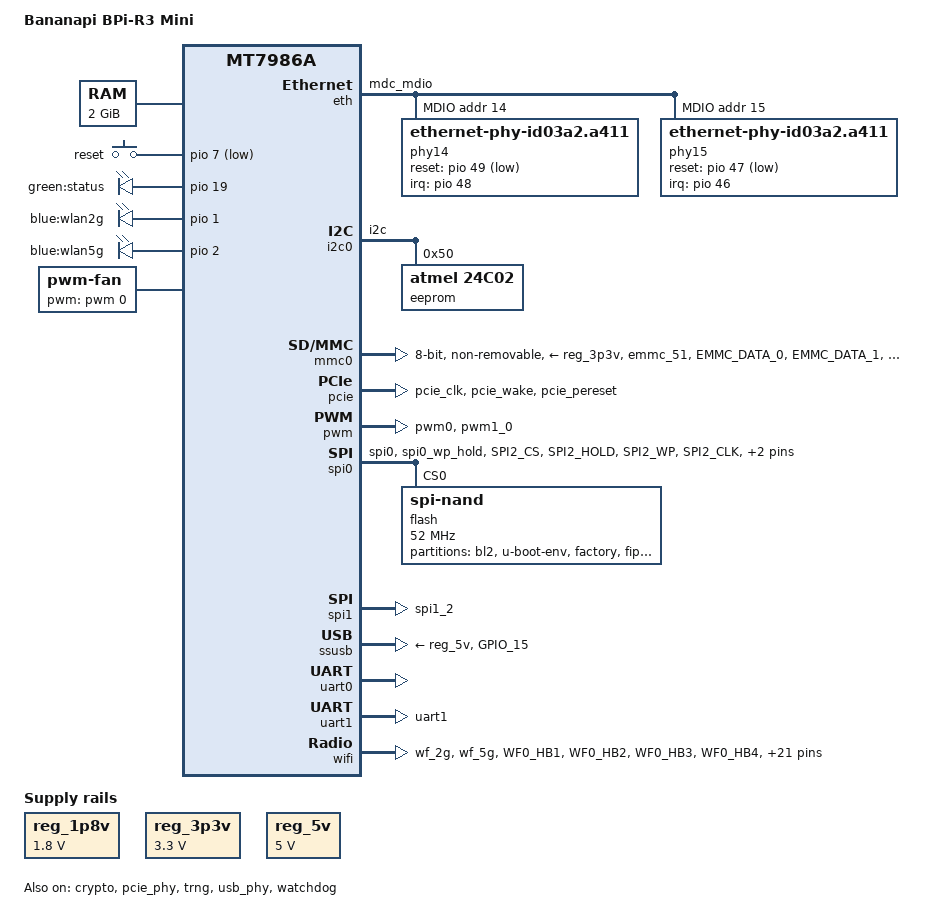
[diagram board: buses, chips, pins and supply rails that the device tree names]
// SPDX-License-Identifier: GPL-2.0-or-later OR MIT
/*
 * Copyright (C) 2023 Tianling Shen <cnsztl@immortalwrt.org>
 */

/dts-v1/;
#include <dt-bindings/gpio/gpio.h>
#include <dt-bindings/input/input.h>
#include <dt-bindings/leds/common.h>

#include "mt7986a.dtsi"

/ {
	model = "Bananapi BPi-R3 Mini";
	chassis-type = "embedded";
	compatible = "bananapi,bpi-r3-mini", "mediatek,mt7986a";

	aliases {
		ethernet0 = &gmac0;
		ethernet1 = &gmac1;
		serial0 = &uart0;

		led-boot = &status_led;
		led-failsafe = &status_led;
		led-running = &status_led;
		led-upgrade = &status_led;
	};

	chosen {
		stdout-path = "serial0:115200n8";
	};

	memory {
		reg = <0 0x40000000 0 0x80000000>;
	};

	gpio-keys {
		compatible = "gpio-keys";

		button-reset {
			label = "reset";
			linux,code = <KEY_RESTART>;
			gpios = <&pio 7 GPIO_ACTIVE_LOW>;
		};
	};

	gpio-leds {
		compatible = "gpio-leds";

		status_led: led-0 {
			label = "green:status";
			gpios = <&pio 19 GPIO_ACTIVE_HIGH>;
		};

		led-1 {
			label = "blue:wlan2g";
			gpios = <&pio 1 GPIO_ACTIVE_HIGH>;
		};

		led-2 {
			label = "blue:wlan5g";
			gpios = <&pio 2 GPIO_ACTIVE_HIGH>;
		};
	};

	fan: pwm-fan {
		compatible = "pwm-fan";
		#cooling-cells = <2>;
		cooling-levels = <0 128 255>;
		pwms = <&pwm 0 10000 0>;
		status = "okay";
	};

	reg_1p8v: regulator-1p8v {
		compatible = "regulator-fixed";
		regulator-name = "fixed-1.8V";
		regulator-min-microvolt = <1800000>;
		regulator-max-microvolt = <1800000>;
		regulator-boot-on;
		regulator-always-on;
	};

	reg_3p3v: regulator-3p3v {
		compatible = "regulator-fixed";
		regulator-name = "fixed-3.3V";
		regulator-min-microvolt = <3300000>;
		regulator-max-microvolt = <3300000>;
		regulator-boot-on;
		regulator-always-on;
	};

	reg_5v: regulator-5v {
		compatible = "regulator-fixed";
		regulator-name = "fixed-5V";
		regulator-min-microvolt = <5000000>;
		regulator-max-microvolt = <5000000>;
		regulator-boot-on;
		regulator-always-on;
	};
};

&cpu_thermal {
	cooling-maps {
		cpu-active-low {
			cooling-device = <&fan 0 0>;
			trip = <&cpu_trip_active_low>;
		};

		cpu-active-med {
			cooling-device = <&fan 1 1>;
			trip = <&cpu_trip_active_med>;
		};

		cpu-active-high {
			cooling-device = <&fan 2 2>;
			trip = <&cpu_trip_active_high>;
		};
	};
};

&crypto {
	status = "okay";
};

&eth {
	status = "okay";
	pinctrl-names = "default";
	pinctrl-0 = <&eth_pins>;

	gmac0: mac@0 {
		compatible = "mediatek,eth-mac";
		reg = <0>;
		phy-mode = "2500base-x";

		fixed-link {
			speed = <2500>;
			full-duplex;
			pause;
		};
	};

	gmac1: mac@1 {
		compatible = "mediatek,eth-mac";
		reg = <1>;
		phy-mode = "2500base-x";

		fixed-link {
			speed = <2500>;
			full-duplex;
			pause;
		};
	};

	mdio: mdio-bus {
		#address-cells = <1>;
		#size-cells = <0>;

		phy14: phy@14 {
			compatible = "ethernet-phy-id03a2.a411";
			reg = <14>;
			pinctrl-names = "default";
			pinctrl-0 = <&en8811_pwr_a>;

			airoha,rx-pol-reverse;

			interrupt-parent = <&pio>;
			interrupts = <48 IRQ_TYPE_LEVEL_HIGH>;
			reset-gpios = <&pio 49 1>;
			reset-assert-us = <10000>;
			reset-deassert-us = <20000>;

			phy-mode = "2500base-x";
			full-duplex;
			pause;
		};

		phy15: phy@15 {
			compatible = "ethernet-phy-id03a2.a411";
			reg = <15>;
			pinctrl-names = "default";
			pinctrl-0 = <&en8811_pwr_b>;

			airoha,rx-pol-reverse;

			interrupt-parent = <&pio>;
			interrupts = <46 IRQ_TYPE_LEVEL_HIGH>;
			reset-gpios = <&pio 47 1>;
			reset-assert-us = <10000>;
			reset-deassert-us = <20000>;

			phy-mode = "2500base-x";
			full-duplex;
			pause;
		};
	};
};

&i2c0 {
	pinctrl-names = "default";
	pinctrl-0 = <&i2c_pins>;
	status = "okay";

	eeprom@50 {
		compatible = "atmel,24c02";
		reg = <0x50>;
		pagesize = <8>;
		size = <256>;
	};
};

&mmc0 {
	pinctrl-names = "default", "state_uhs";
	pinctrl-0 = <&mmc0_pins_default>;
	pinctrl-1 = <&mmc0_pins_uhs>;
	bus-width = <8>;
	max-frequency = <200000000>;
	cap-mmc-highspeed;
	mmc-hs200-1_8v;
	mmc-hs400-1_8v;
	hs400-ds-delay = <0x14014>;
	vmmc-supply = <&reg_3p3v>;
	vqmmc-supply = <&reg_1p8v>;
	non-removable;
	no-sd;
	no-sdio;
	status = "okay";
};

&pcie {
	pinctrl-names = "default";
	pinctrl-0 = <&pcie_pins>;
	status = "okay";
};

&pcie_phy {
	status = "okay";
};

&pio {
	en8811_pwr_a: en8811-pwr-a {
		pins = "GPIO_11";
		drive-strength = <8>;
		mediatek,pull-down-adv = <1>;
		output-low;
	};

	en8811_pwr_b: en8811-pwr-b {
		pins = "GPIO_12";
		drive-strength = <8>;
		mediatek,pull-down-adv = <1>;
		output-low;
	};

	eth_pins: eth-pins {
		mux {
			function = "eth";
			groups = "mdc_mdio";
		};
	};

	i2c_pins: i2c-pins {
		mux {
			function = "i2c";
			groups = "i2c";
		};
	};

	mmc0_pins_default: mmc0-pins-default {
		mux {
			function = "emmc";
			groups = "emmc_51";
		};
		conf-cmd-dat {
			pins = "EMMC_DATA_0", "EMMC_DATA_1", "EMMC_DATA_2",
			       "EMMC_DATA_3", "EMMC_DATA_4", "EMMC_DATA_5",
			       "EMMC_DATA_6", "EMMC_DATA_7", "EMMC_CMD";
			input-enable;
			drive-strength = <4>;
			mediatek,pull-up-adv = <1>;
		};
		conf-clk {
			pins = "EMMC_CK";
			drive-strength = <6>;
			mediatek,pull-down-adv = <2>;
		};
		conf-ds {
			pins = "EMMC_DSL";
			mediatek,pull-down-adv = <2>;
		};
		conf-rst {
			pins = "EMMC_RSTB";
			drive-strength = <4>;
			mediatek,pull-up-adv = <1>;
		};
	};

	mmc0_pins_uhs: mmc0-uhs-pins {
		mux {
			function = "emmc";
			groups = "emmc_51";
		};
		conf-cmd-dat {
			pins = "EMMC_DATA_0", "EMMC_DATA_1", "EMMC_DATA_2",
			       "EMMC_DATA_3", "EMMC_DATA_4", "EMMC_DATA_5",
			       "EMMC_DATA_6", "EMMC_DATA_7", "EMMC_CMD";
			input-enable;
			drive-strength = <4>;
			mediatek,pull-up-adv = <1>;
		};
		conf-clk {
			pins = "EMMC_CK";
			drive-strength = <6>;
			mediatek,pull-down-adv = <2>;
		};
		conf-ds {
			pins = "EMMC_DSL";
			mediatek,pull-down-adv = <2>;
		};
		conf-rst {
			pins = "EMMC_RSTB";
			drive-strength = <4>;
			mediatek,pull-up-adv = <1>;
		};
	};

	pcie_pins: pcie-pins {
		mux {
			function = "pcie";
			groups = "pcie_clk", "pcie_wake", "pcie_pereset";
		};
	};

	pwm_pins: pwm-pins {
		mux {
			function = "pwm";
			groups = "pwm0", "pwm1_0";
		};
	};

	spi_flash_pins: spi-flash-pins {
		mux {
			function = "spi";
			groups = "spi0", "spi0_wp_hold";
		};
		conf-pu {
			pins = "SPI2_CS", "SPI2_HOLD", "SPI2_WP";
			drive-strength = <8>;
			mediatek,pull-up-adv = <0>;
		};
		conf-pd {
			pins = "SPI2_CLK", "SPI2_MOSI", "SPI2_MISO";
			drive-strength = <8>;
			mediatek,pull-down-adv = <0>;
		};
	};

	spic_pins: spic-pins {
		mux {
			function = "spi";
			groups = "spi1_2";
		};
	};

	uart1_pins: uart1-pins {
		mux {
			function = "uart";
			groups = "uart1";
		};
	};

	usb_ngff_pins: usb-ngff-pins {
		ngff-pe-rst {
			pins = "GPIO_7";
			drive-strength = <8>;
			mediatek,pull-up-adv = <1>;
		};
		ngff-wwan-off {
			pins = "GPIO_8";
			drive-strength = <8>;
			mediatek,pull-up-adv = <1>;
		};
		ngff-pwr-off {
			pins = "GPIO_9";
			drive-strength = <8>;
			mediatek,pull-up-adv = <1>;
		};
		ngff-rst {
			pins = "GPIO_10";
			drive-strength = <8>;
			mediatek,pull-up-adv = <1>;
		};
	};

	usb_pwwr_en: usb-pwwr-en {
		pins = "GPIO_15";
		drive-strength = <8>;
		mediatek,pull-down-adv = <1>;
	};

	wf_2g_5g_pins: wf-2g-5g-pins {
		mux {
			function = "wifi";
			groups = "wf_2g", "wf_5g";
		};
		conf {
			pins = "WF0_HB1", "WF0_HB2", "WF0_HB3", "WF0_HB4",
			       "WF0_HB0", "WF0_HB0_B", "WF0_HB5", "WF0_HB6",
			       "WF0_HB7", "WF0_HB8", "WF0_HB9", "WF0_HB10",
			       "WF0_TOP_CLK", "WF0_TOP_DATA", "WF1_HB1",
			       "WF1_HB2", "WF1_HB3", "WF1_HB4", "WF1_HB0",
			       "WF1_HB5", "WF1_HB6", "WF1_HB7", "WF1_HB8",
			       "WF1_TOP_CLK", "WF1_TOP_DATA";
			drive-strength = <4>;
		};
	};

	wf_dbdc_pins: wf-dbdc-pins {
		mux {
			function = "wifi";
			groups = "wf_dbdc";
		};
		conf {
			pins = "WF0_HB1", "WF0_HB2", "WF0_HB3", "WF0_HB4",
			       "WF0_HB0", "WF0_HB0_B", "WF0_HB5", "WF0_HB6",
			       "WF0_HB7", "WF0_HB8", "WF0_HB9", "WF0_HB10",
			       "WF0_TOP_CLK", "WF0_TOP_DATA", "WF1_HB1",
			       "WF1_HB2", "WF1_HB3", "WF1_HB4", "WF1_HB0",
			       "WF1_HB5", "WF1_HB6", "WF1_HB7", "WF1_HB8",
			       "WF1_TOP_CLK", "WF1_TOP_DATA";
			drive-strength = <4>;
		};
	};
};

&pwm {
	pinctrl-names = "default";
	pinctrl-0 = <&pwm_pins>;
	status = "okay";
};

&spi0 {
	pinctrl-names = "default";
	pinctrl-0 = <&spi_flash_pins>;
	status = "okay";

	flash@0 {
		compatible = "spi-nand";
		#address-cells = <1>;
		#size-cells = <1>;
		reg = <0>;

		spi-max-frequency = <52000000>;
		spi-tx-bus-width = <4>;
		spi-rx-bus-width = <4>;

		partitions {
			compatible = "fixed-partitions";
			#address-cells = <1>;
			#size-cells = <1>;

			partition@0 {
				label = "bl2";
				reg = <0x00000 0x100000>;
				read-only;
			};

			partition@100000 {
				label = "u-boot-env";
				reg = <0x100000 0x80000>;
			};

			partition@180000 {
				label = "factory";
				reg = <0x180000 0x200000>;
			};

			partition@380000 {
				label = "fip";
				reg = <0x380000 0x200000>;
				read-only;
			};

			partition@580000 {
				label = "ubi";
				reg = <0x580000 0x7a80000>;
			};
		};
	};
};

&spi1 {
	pinctrl-names = "default";
	pinctrl-0 = <&spic_pins>;
	status = "okay";
};

&ssusb {
	pinctrl-names = "default";
	pinctrl-0 = <&usb_pwwr_en>;
	pinctrl-1 = <&usb_ngff_pins>;
	vusb33-supply = <&reg_3p3v>;
	vbus-supply = <&reg_5v>;
	status = "okay";
};

&trng {
	status = "okay";
};

&uart0 {
	status = "okay";
};

&uart1 {
	pinctrl-names = "default";
	pinctrl-0 = <&uart1_pins>;
	status = "okay";
};

&usb_phy {
	status = "okay";
};

&watchdog {
	status = "okay";
};

&wifi {
	pinctrl-names = "default", "dbdc";
	pinctrl-0 = <&wf_2g_5g_pins>;
	pinctrl-1 = <&wf_dbdc_pins>;
	status = "okay";

	mediatek,eeprom-data = <0x86790000 0x000c4326 0x60000000 0x00000000 0x00000000 0x00000000 0x00000000 0x00000000
				0x00000000 0x00000000 0x00000000 0x00000000 0x00000000 0x00000000 0x00000000 0x00000000
				0x00000000 0x00000000 0x00000000 0x00000000 0x00000000 0x00000000 0x00000000 0x01000000
				0x00000000 0x00000000 0x00000000 0x00000000 0x00000000 0x00000000 0x00000000 0x00000000
				0x00000000 0x00000000 0x00000000 0x00000000 0x00000000 0x00000000 0x00000000 0x00000000
				0x00000000 0x00000000 0x00000000 0x00000000 0x00000000 0x00000000 0x00000000 0x00000000
				0x00000000 0x00000000 0x00000000 0x00000000 0x00000000 0x00000000 0x00000000 0x00000000
				0x00000000 0x00000000 0x00000000 0x00000000 0x00000000 0x00000000 0x00000000 0x00000000
				0x00000000 0x00000800 0x00000000 0x00000000 0x00000000 0x00000000 0x00000000 0x00000000
				0x00000000 0x00000000 0x00000000 0x00000000 0x00000000 0x00000000 0x00000000 0x00000000
				0x00000000 0x00000000 0x00000000 0x00000000 0x00000000 0x00000000 0x00000000 0x00000000
				0x00000000 0x00000000 0x00000000 0x00000000 0x00000000 0x00000000 0x00000000 0x00000000
				0x00000000 0x00000000 0x00000000 0x00000000 0x125b486c 0x013c003f 0x00100000 0x00000000
				0x00000000 0x00000000 0x00000000 0x00000000 0x00000000 0x00000000 0x00000000 0x00000000
				0x00000000 0x00000000 0x00000000 0x00000000 0x00000000 0x00000000 0x00000000 0x00000000
				0x00000000 0x00000000 0x00000000 0x00000000 0x00000000 0x00000000 0x00000000 0x00000000
				0x00000000 0x00000000 0x00000000 0x00000000 0x00000000 0x00000000 0x00000000 0x00000000
				0x00000000 0x00000000 0x00000000 0x00000000 0x00000000 0x00000000 0x00000000 0x00000000
				0x00000000 0x00000000 0x00000000 0x00000000 0x00000000 0x00000000 0x00000000 0x00000000
				0x00000000 0x00000000 0x00000000 0x00000000 0x00000000 0x00000000 0x00000000 0x00000000
				0x00000000 0x00000000 0x00000000 0x00000000 0x00000000 0x00000000 0x00000000 0x00000000
				0x00000000 0x00000000 0x00000000 0x00000000 0x00000000 0x00000000 0x00000000 0x00000000
				0x00000000 0x00000000 0x00000000 0x00000000 0x00000000 0x00000000 0x00000000 0x00000000
				0x00000000 0x00000000 0x00000000 0x00000000 0x00000000 0x00000000 0x00000000 0x00000000
				0x00000000 0x00000000 0x00000000 0x00000000 0x00000000 0x00000000 0x00000000 0x00000000
				0x00000000 0x00000000 0x00000000 0x00000000 0x00000000 0x00000000 0x00000000 0x00000000
				0x00000000 0x00000000 0x00000000 0x00000000 0x00000000 0x00000000 0x00000000 0x00000000
				0x00000000 0x00000000 0x00000000 0x00000000 0x00000000 0x00000000 0x00000000 0x00000000
				0x00000000 0x00000000 0x00000000 0x00000000 0x00000000 0x00000000 0x00000000 0x00000000
				0x00000000 0x00000000 0x00000000 0x00000000 0x00000000 0x00000000 0x00000000 0x00000000
				0x00000000 0x00000000 0x00000000 0x00000000 0x00000000 0x00000000 0x00000000 0x00000000
				0x00000000 0x00050000 0x00000000 0x00000000 0x00000000 0x00000303 0x03030303 0x03030303
				0x03030303 0x03030303 0x03030303 0x03030303 0x03030303 0x03030000 0x00171919 0x19191919
				0x190d0207 0x180f040b 0x170f040b 0x170f040b 0x170f0506 0x160f0506 0x160f0506 0x160f0506
				0x162d2d2d 0x2d2b2b2b 0x2b2b2b2b 0x2b2b2b2b 0x2b2b2b2b 0x2b2b2b2b 0x2b000000 0x00000000
				0x00000000 0x002b2b2b 0x2b292929 0x292b2b2b 0x2b292929 0x292b2b2b 0x2b292929 0x292b2b2b
				0x2b292929 0x29000000 0x00000000 0x00000000 0x00000000 0x00000000 0x00000000 0x00000000
				0x00000000 0x00000000 0x00000000 0x00000000 0x00000000 0x00000000 0x00000000 0x00000000
				0x00000000 0x00000000 0x00000000 0x00000000 0x00000000 0x00000000 0x00000000 0x00000000
				0x00000000 0x00000000 0x00000000 0x00000000 0x00000000 0x00000000 0x00000000 0x00000000
				0x00000000 0x00000000 0x00000000 0x00000000 0x00000000 0x00000000 0x00000000 0x00000000
				0x00000000 0x00000000 0x00000000 0x00000000 0x00000000 0x00000000 0x00000000 0x00000000
				0x00000000 0x00000000 0x00000000 0x00000000 0x00000000 0x00000000 0x00000000 0x00000000
				0x00000000 0x00000000 0x00000000 0x00000000 0x00000000 0x00000000 0x00000000 0x00000000
				0x00000000 0x00000000 0x8080c5c5 0xd1d1d9d9 0xe5e5f1f1 0x40408080 0xc9c9d5d5 0xdddde9e9
				0xf1f14040 0x8080c1c1 0xcdcdd9d9 0xe1e1ebeb 0x40408080 0xbdbdc9c9 0xd5d5dddd 0xe7e74040
				0x00000000 0x00000000 0x00000000 0x00000000 0x00000000 0x00000000 0x00000000 0x00000000
				0x00000000 0x00000000 0x00000000 0x00000000 0x00000000 0x00000000 0x00000000 0x00000000
				0x00000000 0x00000000 0x00000000 0x00000000 0x00000000 0x00000000 0x00000000 0x00000000
				0x00000000 0x00000000 0x00000000 0x00000000 0x00000000 0x00000000 0x00000000 0x00000000
				0x00000000 0x00000000 0x00000000 0x00000000 0x00000000 0x00000000 0x00000000 0x00000000
				0x00000000 0x00000000 0x00000000 0x00000000 0x00000000 0x00000000 0x00000000 0x00000000
				0x00000000 0x00000000 0x00000000 0x00000000 0x00000000 0x00000000 0x00000000 0x00000000
				0x00000000 0x00000000 0x00000000 0x00000000 0x00000000 0x00000000 0x00000000 0x00000000
				0x00000000 0x00000000 0x00000000 0x00000000 0x00000000 0x00000000 0x00000000 0x00000000
				0x00000000 0x00000000 0x00000000 0x00000000 0x00000000 0x00000000 0x00000000 0x00000000
				0x00000000 0x00000000 0x00000000 0x00000000 0x00000000 0x00000000 0x00000000 0x00000000
				0x00000000 0x00000000 0x00000000 0x00000000 0x00000000 0x00000000 0x00000000 0x00000000
				0x00000000 0x00000000 0x00000000 0x00000000 0x00000000 0x00000000 0x00000000 0x00000000
				0x00000000 0x00000000 0x00000000 0x00000000 0x00000000 0x00000000 0x00000000 0x00000000
				0x00000000 0x00000000 0x00000000 0x00000000 0x02000200 0x02000200 0x02000200 0x02000200
				0x02000200 0x02000200 0x02000200 0x02000200 0x02000200 0x02000200 0x02000200 0x02000200
				0x02000200 0x02000200 0x02000200 0x02000200 0x000000c6 0xc6c6c6c4 0x0000c600 0xc6c60000
				0x828484c4 0xc4c40000 0x82848400 0xc6c6c600 0x00828484 0x8686c4c4 0xc4000082 0x84848686
				0xc6c6c600 0x00828484 0x8686c6c6 0xc6000082 0x84848686 0xc6c6c600 0x00828484 0x8686c6c6
				0xc4c300c6 0x00c6c4c3 0xc1008181 0xc6c6c4c3 0xc1008181 0x00c5c5c3 0xc2008182 0x8200c6c6
				0xc4c3c100 0x81818686 0xc6c6c4c3 0xc1008181 0x8686c5c5 0xc3c20081 0x82828787 0xc5c5c3c2
				0x00818282 0x8787c6c6 0xc4c3c100 0x81818686 0xc6c6c4c3 0xc1008181 0x8686c6c6 0xc4c3c100
				0x81818686 0xc6c6c4c3 0x00c6c6c4 0xc3c10081 0x818686c6 0xc6c4c3c1 0x00818186 0x86c5c5c3
				0xc2008182 0x828787c5 0xc5c3c200 0x81828287 0x87c6c6c4 0xc3c10081 0x818686c6 0xc6c4c3c1
				0x00818186 0x86c6c6c4 0xc3c10081 0x81868600 0x00000000 0x00000000 0x00000000 0x00000000
				0x00000000 0x00000000 0x00000000 0x00000000 0x00000000 0x00000000 0x00000000 0x00000000
				0x00000000 0x00000000 0x00000000 0x00000000 0x00000000 0x00000000 0x00000000 0x00000000
				0x00000000 0x00000000 0x00000000 0x00000000 0x00000000 0x00000000 0x00000000 0x00000000
				0x00000000 0x00000000 0x00000000 0x00000000 0x00000000 0x00000000 0x00000000 0x00000000
				0x00000000 0x00000000 0x00000000 0x00000000 0x00000000 0x00000000 0x00000000 0x00000000
				0x00000000 0x00000000 0x00000000 0x00000000 0x00bd0000 0x00000000 0x00000000 0x00000000
				0x00000000 0x00000000 0x00000000 0x00000000 0x00000000 0x00000000 0x00000000 0x00000000
				0x00000000 0x00000000 0x00000000 0x00000000 0x00000000 0x00000000 0x00000000 0x00000000
				0x00000000 0x00000000 0x00000000 0x00000000 0x00000000 0x00000000 0x00000000 0x00000000
				0x00000000 0x00000000 0x00000000 0x00000000 0x00000000 0x00000000 0x00000000 0x00000000
				0x00000000 0x00000000 0x00000000 0x00000000 0x00000000 0x00000000 0x00000000 0x00000000
				0x00000000 0x00000000 0x00000000 0x00000000 0x00000000 0x00000000 0x00000000 0x00000000
				0x00000000 0x00000000 0x00000000 0x00000000 0x00000000 0x00000000 0x00000000 0x00000000
				0x00000000 0x00000000 0x00000000 0x00000000 0x00000000 0x00000000 0x00000000 0x00000000
				0x00000000 0x00000000 0x00000000 0x00000000 0x00000000 0x00000000 0x00000000 0x00000000
				0x00000000 0x00000000 0x00000000 0x00000000 0x00000000 0x00000000 0x00000000 0x00000000
				0x00000000 0x00000000 0x00000000 0x00000000 0x00000000 0x00000000 0x00000000 0x00000000
				0x00000000 0x00000000 0x00000000 0x00000000 0x00000000 0x00000000 0x00000000 0x00000000
				0x00000000 0x00000000 0x00000000 0x00000000 0x00000000 0x00000000 0x00000000 0x00000000
				0x00000000 0x00000000 0x00000000 0x00000000 0x00000000 0x00000000 0x00000000 0x00000000
				0x00000000 0x00000000 0x00000000 0x00000000 0x00000000 0x00000000 0x00000000 0x00000000
				0x00000000 0x00000000 0x00000000 0x00000000 0x00000000 0x00000000 0x00000000 0x00000000
				0x00000000 0x00000000 0x00000000 0x00000000 0x00000000 0x00000000 0x00000000 0x00000000
				0x00000000 0x00000000 0x00000000 0x00000000 0x00000000 0x00000000 0x00000000 0x00000000
				0x00000000 0x00000000 0x00000000 0x00000000 0x00000000 0x00000000 0x00000000 0x00000000
				0x00000000 0x00000000 0x00000000 0x00000000 0x00000000 0x00000000 0x00000000 0x00000000
				0x00000000 0x00000000 0x00000000 0x00000000 0x00000000 0x00000000 0x00000000 0x00000000
				0x00000000 0x00000000 0x00000000 0x00000000 0x00000000 0x00000000 0x00000000 0x00000000
				0x00000000 0x00000000 0x00000000 0x00000000 0x00000000 0x00000000 0x00000000 0x00000000
				0x00000000 0x00000000 0x00000000 0x00000000 0x00000000 0x00000000 0x00000000 0x00000000
				0x00000000 0x00000000 0x00000000 0x00000000 0x00000000 0x00000000 0x00000000 0x00000000
				0x00000000 0x00000000 0x00000000 0x00000000 0x00000000 0x00000000 0x00000000 0x00000000
				0x00000000 0x00000000 0x00000000 0x00000000 0x00000000 0x00000000 0x00000000 0x00000000
				0x2cd22cd2 0x2cd22cd2 0x2bd22bd2 0x2bd22bd2 0x2bd22bd2 0x2bd22bd2 0x2bd22bd2 0x2bd22bd2
				0x2bd22bd2 0x2bd22bd2 0x2bd22bd2 0x2bd22bd2 0x00000000 0x00000000 0x00000000 0x00000000
				0x00000000 0x00000000 0x72f6f2f7 0x72f772f7 0x72f772f6 0x72f472f3 0x72fa72fc 0x72fc72fd
				0x72fc72fb 0x72f972f8 0xf2fb72fe 0x72fe72fe 0x72fe72fd 0x72fb72f9 0xf2f9f2fb 0xf2fb72fb
				0x72fb72fa 0xf2f7f2f6 0x00000000 0x00000000 0x00000000 0x00000000 0x00000000 0x00000000
				0x00000000 0x00000000 0x00000000 0x00000000 0x00000000 0x00000000 0x00000000 0x00d9d9d9
				0x00000000 0x00000000 0x00000000 0x00000000 0x00000000 0x00000000 0x00000000 0x00000000
				0x00000000 0x00000000 0x00000000 0x00000000 0x00000000 0x00000000 0x00000000 0x00000000
				0x00000000 0x00000000 0x00000000 0x00000000 0x00000000 0x00000000 0x00000000 0x00000000
				0x00000000 0x00000000 0x00000000 0x00000000 0x00000000 0x00000000 0x00000000 0x00000000
				0x00000000 0x00000000 0x00000000 0x00000000 0x00000000 0x00000000 0x00000000 0x00000000
				0x00000000 0x00000000 0x00000000 0x00000000 0x00000000 0x00000000 0x00000000 0x00000000
				0x00000000 0x00000000 0x00000000 0x00000000 0x00000000 0x00000000 0x00000000 0x00000000
				0x00000000 0x00000000 0x00000000 0x00000000 0x00000000 0x00000000 0x00000000 0x00000000
				0x00000000 0x00000000 0x00000000 0x00000000 0x00000000 0x00000000 0x00000000 0x00000000
				0x00000000 0x00000000 0x00000000 0x00000000 0x00000000 0x00000000 0x00000000 0x00000000
				0x00000000 0x00000000 0x00000000 0x00000000 0x00000000 0x00000000 0x00000000 0x00000000
				0x00000000 0x00000000 0x00000000 0x00000000 0x00000000 0x00000000 0x00000000 0x00000000
				0x00000000 0x00000000 0x00000000 0x00000000 0x00000000 0x00000000 0x00000000 0x00000000
				0x00000000 0x00000000 0x00000000 0x00000000 0x00000000 0x00000000 0x00000000 0x00000000
				0x00000000 0x00000000 0x00000000 0x00000000 0x00000000 0x00000000 0x00000000 0x00000000
				0x00000000 0x00000000 0x00000000 0x00000000 0x00000000 0x00000000 0x00000000 0x00000000
				0x00000000 0x00000000 0x00000000 0x00000000 0x00000000 0x00000000 0x00000000 0x00000000
				0x00000000 0x00000000 0x00000000 0x00000000 0x00000000 0x00000000 0x00000000 0x00000000>;
};
